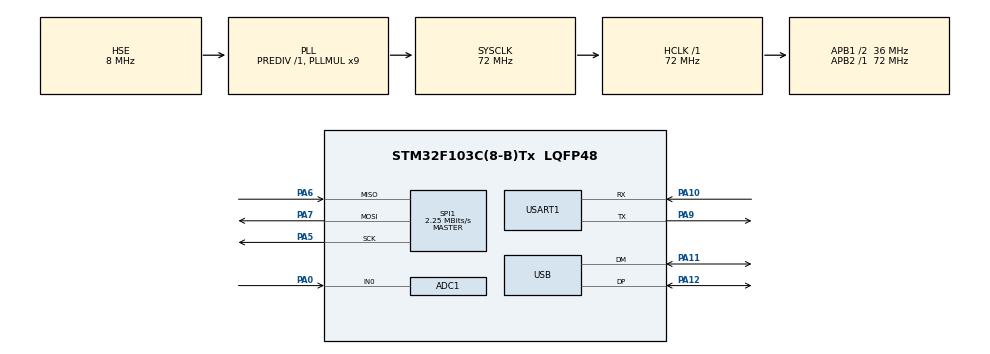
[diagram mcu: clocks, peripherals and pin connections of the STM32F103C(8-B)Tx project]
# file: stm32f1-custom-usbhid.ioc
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ADC1.Channel-0\#ChannelRegularConversion=ADC_CHANNEL_0
ADC1.NbrOfConversionFlag=1
ADC1.Rank-0\#ChannelRegularConversion=1
ADC1.SamplingTime-0\#ChannelRegularConversion=ADC_SAMPLETIME_1CYCLE_5
ADC1.master=1
Mcu.Family=STM32F1
Mcu.Name=STM32F103C(8-B)Tx
Mcu.Package=LQFP48
NVIC.PriorityGroup=NVIC_PRIORITYGROUP_4
NVIC.USART1_IRQn=true\:0\:0\:false
NVIC.USB_LP_CAN1_RX0_IRQn=true\:0\:0\:false
PA0-WKUP.Signal=ADCx_IN0
PA10.Mode=Asynchronous
PA10.Signal=USART1_RX
PA11.Mode=Device
PA11.Signal=USB_DM
PA12.Mode=Device
PA12.Signal=USB_DP
PA13.Mode=Serial_Wire
PA13.Signal=SYS_JTMS-SWDIO
PA14.Mode=Serial_Wire
PA14.Signal=SYS_JTCK-SWCLK
PA5.Mode=Full_Duplex_Master
PA5.Signal=SPI1_SCK
PA6.Mode=Full_Duplex_Master
PA6.Signal=SPI1_MISO
PA7.Mode=Full_Duplex_Master
PA7.Signal=SPI1_MOSI
PA9.Mode=Asynchronous
PA9.Signal=USART1_TX
PD0-OSC_IN.Mode=HSE-External-Oscillator
PD0-OSC_IN.Signal=RCC_OSC_IN
PD1-OSC_OUT.Mode=HSE-External-Oscillator
PD1-OSC_OUT.Signal=RCC_OSC_OUT
ProjectManager.TargetToolchain=TrueSTUDIO
RCC.ADCPresc=RCC_ADCPCLK2_DIV6
RCC.AHBFreq_Value=72000000
RCC.APB1CLKDivider=RCC_HCLK_DIV2
RCC.APB1Freq_Value=36000000
RCC.APB1TimFreq_Value=72000000
RCC.APB2Freq_Value=72000000
RCC.APB2TimFreq_Value=72000000
RCC.HCLKFreq_Value=72000000
RCC.HSIState=RCC_HSI_ON
RCC.PLLMUL=RCC_PLL_MUL9
RCC.SYSCLKFreq_VALUE=72000000
RCC.SYSCLKSource=RCC_SYSCLKSOURCE_PLLCLK
RCC.USBFreq_Value=48000000
RCC.USBPrescaler=RCC_USBPLLCLK_DIV1_5
SH.ADCx_IN0.0=ADC1_IN0,IN0
SPI1.BaudRatePrescaler=SPI_BAUDRATEPRESCALER_32
SPI1.CalculateBaudRate=2.25 MBits/s
SPI1.Mode=SPI_MODE_MASTER
USB_DEVICE.USBD_HandleTypeDef=hUsbDeviceFS
USB_DEVICE.VirtualMode=CustomHid
USB_DEVICE.VirtualModeFS=Custom_Hid_FS
VP_USB_DEVICE_VS_USB_DEVICE_CUSTOM_HID_FS.Mode=CUSTOM_HID_FS
board=foo

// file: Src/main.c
/**
  ******************************************************************************
  * File Name          : main.c
  * Description        : Main program body
  ******************************************************************************
  *
  * COPYRIGHT(c) 2015 STMicroelectronics
  *
  * Redistribution and use in source and binary forms, with or without modification,
  * are permitted provided that the following conditions are met:
  *   1. Redistributions of source code must retain the above copyright notice,
  *      this list of conditions and the following disclaimer.
  *   2. Redistributions in binary form must reproduce the above copyright notice,
  *      this list of conditions and the following disclaimer in the documentation
  *      and/or other materials provided with the distribution.
  *   3. Neither the name of STMicroelectronics nor the names of its contributors
  *      may be used to endorse or promote products derived from this software
  *      without specific prior written permission.
  *
  * THIS SOFTWARE IS PROVIDED BY THE COPYRIGHT HOLDERS AND CONTRIBUTORS "AS IS"
  * AND ANY EXPRESS OR IMPLIED WARRANTIES, INCLUDING, BUT NOT LIMITED TO, THE
  * IMPLIED WARRANTIES OF MERCHANTABILITY AND FITNESS FOR A PARTICULAR PURPOSE ARE
  * DISCLAIMED. IN NO EVENT SHALL THE COPYRIGHT HOLDER OR CONTRIBUTORS BE LIABLE
  * FOR ANY DIRECT, INDIRECT, INCIDENTAL, SPECIAL, EXEMPLARY, OR CONSEQUENTIAL
  * DAMAGES (INCLUDING, BUT NOT LIMITED TO, PROCUREMENT OF SUBSTITUTE GOODS OR
  * SERVICES; LOSS OF USE, DATA, OR PROFITS; OR BUSINESS INTERRUPTION) HOWEVER
  * CAUSED AND ON ANY THEORY OF LIABILITY, WHETHER IN CONTRACT, STRICT LIABILITY,
  * OR TORT (INCLUDING NEGLIGENCE OR OTHERWISE) ARISING IN ANY WAY OUT OF THE USE
  * OF THIS SOFTWARE, EVEN IF ADVISED OF THE POSSIBILITY OF SUCH DAMAGE.
  *
  ******************************************************************************
  */
#include "stm32f1xx_hal.h"
#include "usb_device.h"

ADC_HandleTypeDef hadc1;

SPI_HandleTypeDef hspi1;

UART_HandleTypeDef huart1;

/* USER CODE BEGIN PV */
/* Private variables ---------------------------------------------------------*/

/* USER CODE END PV */

void SystemClock_Config(void);
static void MX_GPIO_Init(void);
static void MX_ADC1_Init(void);
static void MX_SPI1_Init(void);
static void MX_USART1_UART_Init(void);

/* USER CODE BEGIN PFP */
/* Private function prototypes -----------------------------------------------*/

/* USER CODE END PFP */

/* USER CODE BEGIN 0 */
extern int8_t USBD_CUSTOM_HID_SendReport_FS (uint8_t *report,uint16_t len);
/* USER CODE END 0 */

int main(void)
{

  /* MCU Configuration----------------------------------------------------------*/

  /* Reset of all peripherals, Initializes the Flash interface and the Systick. */
  HAL_Init();

  /* Configure the system clock */
  SystemClock_Config();

  /* Initialize all configured peripherals */
  MX_GPIO_Init();
  MX_ADC1_Init();
  MX_SPI1_Init();
  MX_USART1_UART_Init();
  MX_USB_DEVICE_Init();

  /* Infinite loop */
  /* USER CODE BEGIN WHILE */
  uint8_t report = 0;

  while (1)
  {
    /* USER CODE END WHILE */
    HAL_Delay(500);

    USBD_CUSTOM_HID_SendReport_FS(&report, 1);
    report = !report;
  }

}

/** System Clock Configuration
*/
void SystemClock_Config(void)
{

  RCC_OscInitTypeDef RCC_OscInitStruct;
  RCC_ClkInitTypeDef RCC_ClkInitStruct;
  RCC_PeriphCLKInitTypeDef PeriphClkInit;

  RCC_OscInitStruct.OscillatorType = RCC_OSCILLATORTYPE_HSE;
  RCC_OscInitStruct.HSEState = RCC_HSE_ON;
  RCC_OscInitStruct.HSEPredivValue = RCC_HSE_PREDIV_DIV1;
  RCC_OscInitStruct.PLL.PLLState = RCC_PLL_ON;
  RCC_OscInitStruct.PLL.PLLSource = RCC_PLLSOURCE_HSE;
  RCC_OscInitStruct.PLL.PLLMUL = RCC_PLL_MUL9;
  HAL_RCC_OscConfig(&RCC_OscInitStruct);

  RCC_ClkInitStruct.ClockType = RCC_CLOCKTYPE_SYSCLK|RCC_CLOCKTYPE_PCLK1;
  RCC_ClkInitStruct.SYSCLKSource = RCC_SYSCLKSOURCE_PLLCLK;
  RCC_ClkInitStruct.AHBCLKDivider = RCC_SYSCLK_DIV1;
  RCC_ClkInitStruct.APB1CLKDivider = RCC_HCLK_DIV2;
  RCC_ClkInitStruct.APB2CLKDivider = RCC_HCLK_DIV1;
  HAL_RCC_ClockConfig(&RCC_ClkInitStruct, FLASH_LATENCY_2);

  PeriphClkInit.PeriphClockSelection = RCC_PERIPHCLK_ADC|RCC_PERIPHCLK_USB;
  PeriphClkInit.AdcClockSelection = RCC_ADCPCLK2_DIV6;
  PeriphClkInit.UsbClockSelection = RCC_USBPLLCLK_DIV1_5;
  HAL_RCCEx_PeriphCLKConfig(&PeriphClkInit);

  HAL_SYSTICK_Config(HAL_RCC_GetHCLKFreq()/1000);

  HAL_SYSTICK_CLKSourceConfig(SYSTICK_CLKSOURCE_HCLK);

}

/* ADC1 init function */
void MX_ADC1_Init(void)
{

  ADC_ChannelConfTypeDef sConfig;

    /**Common config
    */
  hadc1.Instance = ADC1;
  hadc1.Init.ScanConvMode = ADC_SCAN_DISABLE;
  hadc1.Init.ContinuousConvMode = DISABLE;
  hadc1.Init.DiscontinuousConvMode = DISABLE;
  hadc1.Init.ExternalTrigConv = ADC_SOFTWARE_START;
  hadc1.Init.DataAlign = ADC_DATAALIGN_RIGHT;
  hadc1.Init.NbrOfConversion = 1;
  HAL_ADC_Init(&hadc1);

    /**Configure Regular Channel
    */
  sConfig.Channel = ADC_CHANNEL_0;
  sConfig.Rank = 1;
  sConfig.SamplingTime = ADC_SAMPLETIME_1CYCLE_5;
  HAL_ADC_ConfigChannel(&hadc1, &sConfig);

}

/* SPI1 init function */
void MX_SPI1_Init(void)
{

  hspi1.Instance = SPI1;
  hspi1.Init.Mode = SPI_MODE_MASTER;
  hspi1.Init.Direction = SPI_DIRECTION_2LINES;
  hspi1.Init.DataSize = SPI_DATASIZE_8BIT;
  hspi1.Init.CLKPolarity = SPI_POLARITY_LOW;
  hspi1.Init.CLKPhase = SPI_PHASE_1EDGE;
  hspi1.Init.NSS = SPI_NSS_SOFT;
  hspi1.Init.BaudRatePrescaler = SPI_BAUDRATEPRESCALER_32;
  hspi1.Init.FirstBit = SPI_FIRSTBIT_MSB;
  hspi1.Init.TIMode = SPI_TIMODE_DISABLED;
  hspi1.Init.CRCCalculation = SPI_CRCCALCULATION_DISABLED;
  hspi1.Init.CRCPolynomial = 10;
  HAL_SPI_Init(&hspi1);

}

/* USART1 init function */
void MX_USART1_UART_Init(void)
{

  huart1.Instance = USART1;
  huart1.Init.BaudRate = 115200;
  huart1.Init.WordLength = UART_WORDLENGTH_8B;
  huart1.Init.StopBits = UART_STOPBITS_1;
  huart1.Init.Parity = UART_PARITY_NONE;
  huart1.Init.Mode = UART_MODE_TX_RX;
  huart1.Init.HwFlowCtl = UART_HWCONTROL_NONE;
  huart1.Init.OverSampling = UART_OVERSAMPLING_16;
  HAL_UART_Init(&huart1);

}

/** Configure pins as
        * Analog
        * Input
        * Output
        * EVENT_OUT
        * EXTI
*/
void MX_GPIO_Init(void)
{

  /* GPIO Ports Clock Enable */
  __GPIOD_CLK_ENABLE();
  __GPIOA_CLK_ENABLE();

}

/************************ (C) COPYRIGHT STMicroelectronics *****END OF FILE****/
